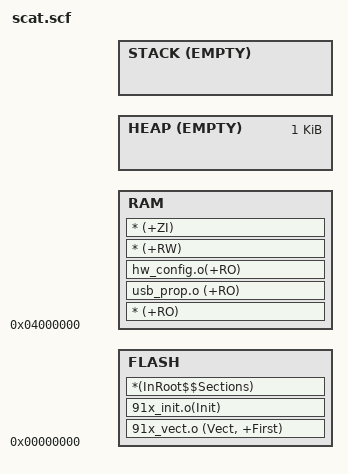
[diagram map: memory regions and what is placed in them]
;******************** (C) COPYRIGHT 2006 STMicroelectronics ********************
;* File Name          : scat_flash.scf
;* Author             : MCD Application Team
;* Date First Issued  : 10/01/2006 : V1.0
;* Description        : This file provides an example of a scatterloading
;*                      descriptor file that defines one load region in the
;*                      Embedded Flash(Bank 0) and four execution regions.
;********************************************************************************
;* History:
;* 10/01/2006 : V1.0
;*******************************************************************************
; THE PRESENT SOFTWARE WHICH IS FOR GUIDANCE ONLY AIMS AT PROVIDING CUSTOMERS
; WITH CODING INFORMATION REGARDING THEIR PRODUCTS IN ORDER FOR THEM TO SAVE TIME.
; AS A RESULT, STMICROELECTRONICS SHALL NOT BE HELD LIABLE FOR ANY DIRECT,
; INDIRECT OR CONSEQUENTIAL DAMAGES WITH RESPECT TO ANY CLAIMS ARISING FROM THE
; CONTENT OF SUCH SOFTWARE AND/OR THE USE MADE BY CUSTOMERS OF THE CODING
; INFORMATION CONTAINED HEREIN IN CONNECTION WITH THEIR PRODUCTS.
;*******************************************************************************


; Embedded Flash Bank1 (32Kbytes)
; The user has to change the flash memory length depending on the used STR91xFxxx 
; device

FLASH_MODE 0x00000000 0x8000
{
    FLASH 0x00000000
    {
        91x_vect.o (Vect, +First)
        91x_init.o(Init)
        *(InRoot$$Sections)        ; this section must be in a root region
    }
    RAM  0x04000000
    {
        * (+RO)
        usb_prop.o (+RO)
        hw_config.o(+RO) ; contains flash routines
        * (+RW)
        * (+ZI)
    }

    ; Heap will grow just above ZI region :
    ; This Symbol is exported to "91x_init.s" file

    HEAP +0 EMPTY 0x400
    {
    }

    ; Stack Base address exported to "91x_init.s" file ( Top of SRAM )

    STACK 0x04018000 EMPTY -0x0
    {
    }
}
;******************* (C) COPYRIGHT 2006 STMicroelectronics *****END OF FILE*****
